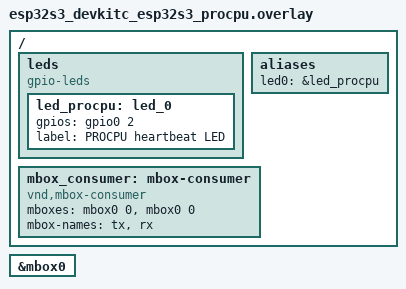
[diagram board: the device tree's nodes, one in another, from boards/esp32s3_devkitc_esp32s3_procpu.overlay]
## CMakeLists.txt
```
cmake_minimum_required(VERSION 3.20.0)

find_package(Zephyr REQUIRED HINTS $ENV{ZEPHYR_BASE})
project(02_mbox_doorbell_procpu)

target_sources(app PRIVATE src/main.c)
```

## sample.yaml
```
sample:
  name: 02 MBOX Doorbell (signal-only, bidirectional)
  description: >
    First real inter-processor communication lab in this series. Uses
    Zephyr's MBOX API (espressif,mbox-esp32 / &mbox0) as a pure signal-only
    "doorbell" - no data payload - in both directions: the onboard BOOT
    button on procpu rings appcpu's doorbell (visible as an LED reaction),
    and appcpu rings procpu's doorbell on a timer (visible as a log line).
    &ipm0 is intentionally left disabled - confirmed on real hardware that
    &mbox0 alone releases appcpu from reset (see the doc for details).
common:
  sysbuild: true
tests:
  sample.boards.espressif.esp32s3_devkitc.mbox_doorbell:
    build_only: true
    platform_allow: esp32s3_devkitc/esp32s3/procpu
    tags:
      - ipc
      - amp
      - esp32s3
      - mbox
```

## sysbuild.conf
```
# sysbuild.conf - sysbuild's OWN Kconfig namespace (SB_CONFIG_*), not the
# app's prj.conf.
#
# Espressif boards default to building MCUboot alongside the app whenever
# --sysbuild is used. This lab has nothing to do with OTA/firmware
# upgrades - it's a plain two-image AMP build (procpu + appcpu) - so
# MCUboot is unwanted overhead here.
SB_CONFIG_BOOTLOADER_NONE=y
SB_CONFIG_BOOTLOADER_MCUBOOT=n
```

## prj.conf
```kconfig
# 02_MBOX_DOORBELL_LAB - core0 (procpu) image
#
# This lab's real teaching content: the MBOX API (mbox.h), used purely as
# a signal-only doorbell (mbox_send_dt(..., NULL) - no payload) in both
# directions between procpu and appcpu.
#
# NOTE: &ipm0 is intentionally left DISABLED here. &ipm0 and &mbox0 are two
# different Zephyr driver bindings for the exact same underlying hardware
# (see doc) - enabling &mbox0 alone is enough to release appcpu from reset,
# confirmed on real hardware, so &ipm0 is left off to avoid two drivers
# competing for the same interrupt sources. Every dual-core/IPC lab in this
# series enables whichever of ipm0/mbox0 matches what it actually teaches.

CONFIG_GPIO=y
CONFIG_MBOX=y

CONFIG_LOG=y
CONFIG_LOG_MODE_IMMEDIATE=y
```

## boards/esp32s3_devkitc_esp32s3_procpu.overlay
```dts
/*
 * Overlay for 02_MBOX_DOORBELL_LAB - core0 (procpu) image
 *
 * Reuses this series' GPIO2 "led0" heartbeat LED convention from Lab 01
 * (see 01_HELLO_DUALCORE_LAB doc). The trigger button is NOT wired
 * externally - it reuses the DevKitC-1's own onboard BOOT button, which
 * mainline Zephyr's esp32s3_devkitc board files already expose as the
 * "sw0" alias (GPIO0, active-low, internal pull-up already configured -
 * see zephyr/boards/espressif/esp32s3_devkitc/esp32s3_devkitc_procpu.dts).
 * No extra wiring is needed for the button.
 *
 * The "mbox-consumer" node below follows Zephyr's own convention for
 * MBOX consumers (see zephyr/samples/drivers/mbox's app overlay): a node
 * with `mboxes`/`mbox-names` phandle-array properties, using the
 * `compatible = "vnd,mbox-consumer"` binding that already ships in
 * mainline Zephyr (dts/bindings/test/vnd,mbox-consumer.yaml) purely so
 * MBOX_DT_SPEC_GET(DT_PATH(mbox_consumer), ...) has something to read -
 * it is not tied to any real driver.
 *
 * ESP32's soft MBOX hardware only has one channel per direction (see
 * doc), so "tx" and "rx" both point at &mbox0 channel 0 - direction is
 * determined by which core (procpu/appcpu) is running this image, not by
 * the channel number.
 */

#include <zephyr/dt-bindings/gpio/gpio.h>

/ {
	leds {
		compatible = "gpio-leds";
		led_procpu: led_0 {
			gpios = <&gpio0 2 GPIO_ACTIVE_HIGH>;
			label = "PROCPU heartbeat LED";
		};
	};

	aliases {
		led0 = &led_procpu;
	};

	mbox_consumer: mbox-consumer {
		compatible = "vnd,mbox-consumer";
		mboxes = <&mbox0 0>, <&mbox0 0>;
		mbox-names = "tx", "rx";
	};
};

/*
 * &ipm0 stays disabled here on purpose (see prj.conf) - only &mbox0 is
 * enabled. Confirmed on real hardware that &mbox0 alone is enough to
 * release appcpu from reset; see the doc for why &ipm0 and &mbox0 are
 * not both enabled together.
 */
&mbox0 {
	status = "okay";
};
```

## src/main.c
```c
/*
 * main.c - 02_MBOX_DOORBELL_LAB (core0 / procpu image)
 *
 * This core does three independent things in one loop:
 *   1. Blinks its own heartbeat LED (GPIO2) every 500ms, same as Lab 01.
 *   2. Polls the onboard BOOT button (sw0 / GPIO0). On each press, it
 *      rings appcpu's doorbell over MBOX - a pure signal, no data at all
 *     ( mbox_send_dt with a NULL msg).
 *   3. Listens for appcpu's own doorbell (appcpu rings it on a timer -
 *      see remote/src/main.c) and logs each one it receives.
 *
 * This is deliberately "signal-only" MBOX usage: nothing but the fact
 * that a doorbell rang is ever communicated. Sending actual data over
 * IPC is a later lab's topic.
 */

#include <zephyr/kernel.h>
#include <zephyr/drivers/gpio.h>
#include <zephyr/drivers/mbox.h>
#include <zephyr/logging/log.h>

LOG_MODULE_REGISTER(app_procpu, LOG_LEVEL_INF);

static const struct gpio_dt_spec led = GPIO_DT_SPEC_GET(DT_ALIAS(led0), gpios);
static const struct gpio_dt_spec button = GPIO_DT_SPEC_GET(DT_ALIAS(sw0), gpios);

static const struct mbox_dt_spec tx_channel = MBOX_DT_SPEC_GET(DT_PATH(mbox_consumer), tx);
static const struct mbox_dt_spec rx_channel = MBOX_DT_SPEC_GET(DT_PATH(mbox_consumer), rx);

#define LED_PERIOD_MS  500
#define POLL_PERIOD_MS 20

static volatile uint32_t doorbell_rx_count;

/* Called (from ISR context) whenever appcpu rings its doorbell. Signal-only
 * doorbell, so `data` carries nothing useful here - just count and log.
 */
static void doorbell_from_appcpu(const struct device *dev, mbox_channel_id_t channel_id,
				  void *user_data, struct mbox_msg *data)
{
	ARG_UNUSED(dev);
	ARG_UNUSED(channel_id);
	ARG_UNUSED(user_data);
	ARG_UNUSED(data);

	doorbell_rx_count++;
	LOG_INF("doorbell from appcpu received (count=%u)", doorbell_rx_count);
}

int main(void)
{
	LOG_INF("02_MBOX_DOORBELL_LAB (core0/procpu) starting");

	if (!gpio_is_ready_dt(&led) || !gpio_is_ready_dt(&button)) {
		LOG_ERR("led or button gpio not ready");
		return -1;
	}

	if (gpio_pin_configure_dt(&led, GPIO_OUTPUT_INACTIVE)) {
		LOG_ERR("failed to configure led");
		return -1;
	}

	if (gpio_pin_configure_dt(&button, GPIO_INPUT)) {
		LOG_ERR("failed to configure button");
		return -1;
	}

	mbox_register_callback_dt(&rx_channel, doorbell_from_appcpu, NULL);
	mbox_set_enabled_dt(&rx_channel, true);

	bool led_state = false;
	bool button_prev = false;
	int64_t next_led_toggle = k_uptime_get() + LED_PERIOD_MS;

	while (1) {
		bool button_now = gpio_pin_get_dt(&button) > 0;

		if (button_now && !button_prev) {
			LOG_INF("button pressed - ringing appcpu's doorbell");
			int ret = mbox_send_dt(&tx_channel, NULL);

			if (ret < 0) {
				LOG_ERR("mbox_send_dt failed (%d)", ret);
			}
		}
		button_prev = button_now;

		int64_t now = k_uptime_get();

		if (now >= next_led_toggle) {
			led_state = !led_state;
			gpio_pin_set_dt(&led, led_state);
			LOG_INF("procpu heartbeat - LED %s", led_state ? "ON" : "OFF");
			next_led_toggle = now + LED_PERIOD_MS;
		}

		k_msleep(POLL_PERIOD_MS);
	}

	return 0;
}
```
